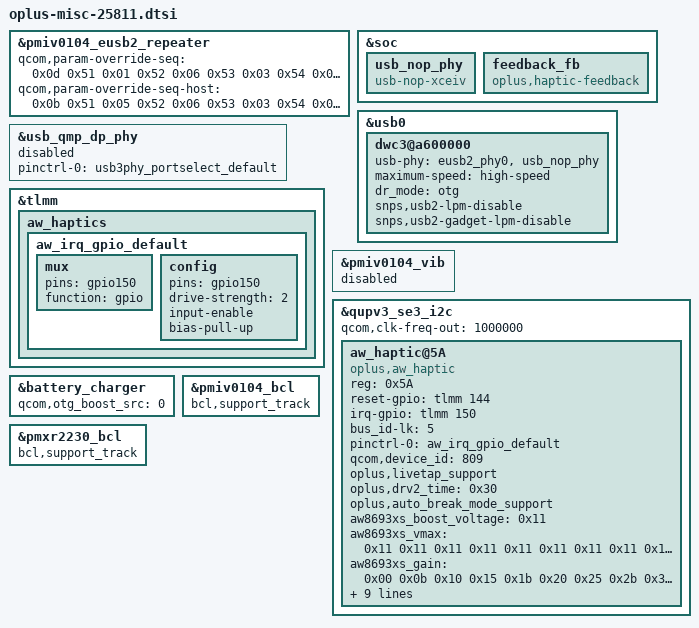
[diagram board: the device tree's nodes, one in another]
&pmiv0104_eusb2_repeater {
	qcom,param-override-seq = <0x0d 0x51 0x01 0x52 0x06 0x53 0x03 0x54 0x03 0x55 0x05 0x57>;
	qcom,param-override-seq-host = <0x0b 0x51 0x05 0x52 0x06 0x53 0x03 0x54 0x00 0x55 0x03 0x57>;
};

&soc {
	usb_nop_phy: usb_nop_phy {
		compatible = "usb-nop-xceiv";
	};
};

&usb0 {
/delete-property/ extcon;
	dwc3@a600000 {
		usb-phy = <&eusb2_phy0>, <&usb_nop_phy>;
		maximum-speed = "high-speed";
		dr_mode = "otg";
		snps,usb2-lpm-disable;
		snps,usb2-gadget-lpm-disable;
	};
};

&usb_qmp_dp_phy {
	pinctrl-names = "default";
	pinctrl-0 = <&usb3phy_portselect_default>;
	status = "disabled";
};

&tlmm {
	aw_haptics: aw_haptics {
		aw_irq_gpio_default: aw_irq_gpio_default {
			mux {
				pins = "gpio150";
				function = "gpio";
			};

			config {
				pins = "gpio150";
				drive-strength = <2>;
				input-enable;
				bias-pull-up;
			};
		};
	};
};

&pmiv0104_vib {
	status = "disabled";
};


&qupv3_se3_i2c {
	qcom,clk-freq-out = <1000000>;
	status = "ok";
	aw_haptic@5A {
		status = "ok";
		compatible = "oplus,aw_haptic";
		reg = <0x5A>;
		reset-gpio = <&tlmm 144 0>;
		irq-gpio = <&tlmm 150 0>;
		bus_id-lk = <5>;
		pinctrl-names = "default";
		pinctrl-0 = <&aw_irq_gpio_default>;

		qcom,device_id = <809>; /* 809 */

		oplus,livetap_support;
		oplus,drv2_time = /bits/ 8 <0x30>;
		oplus,auto_break_mode_support;

		aw8693xs_boost_voltage = <0x11>;
		aw8693xs_vmax = /bits/ 8 < 0x11 0x11 0x11 0x11 0x11 0x11 0x11 0x11 0x11 0x11 0x11 0x11
					0x11 0x11 0x11 0x11 0x11 0x11 0x11 0x11 0x11 0x11 0x11 0x11 0x11 >;
		aw8693xs_gain = /bits/ 8 < 0x00 0x0b 0x10 0x15 0x1b 0x20 0x25 0x2b 0x31 0x36 0x3c 0x41
					0x47 0x50 0x5a 0x60 0x64 0x67 0x6b 0x6e 0x72 0x75 0x79 0x7c 0x7e >;
		aw8693xs_cont_brk_gain = /bits/ 8 < 0x08 >;
		aw8693xs_cont_brk_time = /bits/ 8 < 0x08 >;
		aw8693xs_d2s_gain = /bits/ 8 < 0x07 >;
		aw8693xs_bemf_d2s_gain = /bits/ 8 < 0x04 >;
		aw8693xs_is_enabled_vbat_pro;
		oplus,vbat_low_soc = <5>;
		oplus,vbat_low_soc_cold = <20>;
		oplus,vbat_low_temp = <(-50)>; /*-5C*/
		oplus,vbat_low_vmax_level = <2000>;
	};
};

&soc {
	feedback_fb: feedback_fb {
		compatible = "oplus,haptic-feedback";
	};
};

&battery_charger {
        qcom,otg_boost_src = <0>; /* 0:plat_pmic 1:external */
};

&pmiv0104_bcl {
	bcl,support_track;
};

&pmxr2230_bcl {
	bcl,support_track;
};
